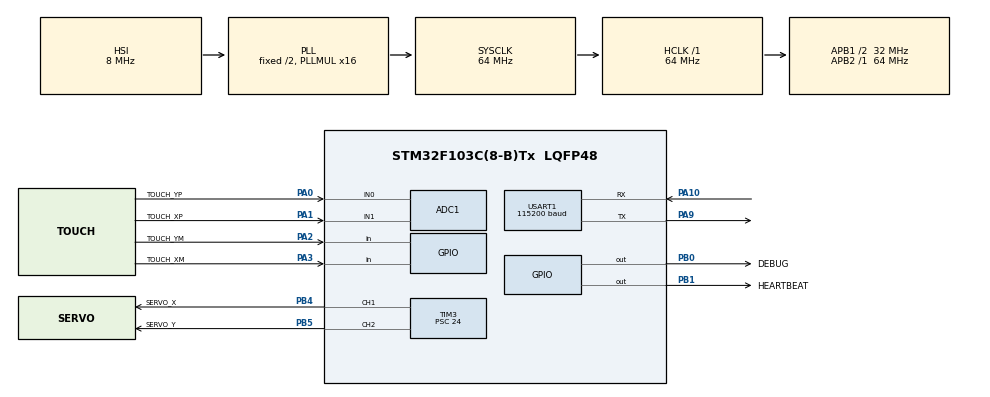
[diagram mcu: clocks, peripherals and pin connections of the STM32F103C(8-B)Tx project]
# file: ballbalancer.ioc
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ADC1.Channel-10\#ChannelRegularConversion=ADC_CHANNEL_0
ADC1.ContinuousConvMode=ENABLE
ADC1.EnableRegularConversion=ENABLE
ADC1.InjNumberOfConversion=0
ADC1.NbrOfConversionFlag=1
ADC1.Rank-10\#ChannelRegularConversion=1
ADC1.SamplingTime-10\#ChannelRegularConversion=ADC_SAMPLETIME_1CYCLE_5
ADC1.master=1
Dma.Request0=USART1_TX
Dma.Request1=USART1_RX
Dma.USART1_RX.1.Direction=DMA_PERIPH_TO_MEMORY
Dma.USART1_RX.1.Instance=DMA1_Channel5
Dma.USART1_RX.1.MemDataAlignment=DMA_MDATAALIGN_BYTE
Dma.USART1_RX.1.MemInc=DMA_MINC_ENABLE
Dma.USART1_RX.1.Mode=DMA_CIRCULAR
Dma.USART1_RX.1.PeriphDataAlignment=DMA_PDATAALIGN_BYTE
Dma.USART1_RX.1.PeriphInc=DMA_PINC_DISABLE
Dma.USART1_RX.1.Priority=DMA_PRIORITY_LOW
Dma.USART1_TX.0.Direction=DMA_MEMORY_TO_PERIPH
Dma.USART1_TX.0.Instance=DMA1_Channel4
Dma.USART1_TX.0.MemDataAlignment=DMA_MDATAALIGN_BYTE
Dma.USART1_TX.0.MemInc=DMA_MINC_ENABLE
Dma.USART1_TX.0.Mode=DMA_NORMAL
Dma.USART1_TX.0.PeriphDataAlignment=DMA_PDATAALIGN_BYTE
Dma.USART1_TX.0.PeriphInc=DMA_PINC_DISABLE
Dma.USART1_TX.0.Priority=DMA_PRIORITY_LOW
FREERTOS.INCLUDE_vTaskDelayUntil=1
FREERTOS.Tasks01=control,3,512,controlTask,As weak,NULL,Dynamic,NULL,NULL
FREERTOS.configTOTAL_HEAP_SIZE=10000
Mcu.Family=STM32F1
Mcu.Name=STM32F103C(8-B)Tx
Mcu.Package=LQFP48
NVIC.DMA1_Channel4_IRQn=true\:5\:0\:false\:false\:true\:true\:false
NVIC.DMA1_Channel5_IRQn=true\:5\:0\:false\:false\:true\:true\:false
NVIC.PriorityGroup=NVIC_PRIORITYGROUP_4
NVIC.TIM3_IRQn=true\:5\:0\:false\:false\:true\:true\:true
NVIC.USART1_IRQn=true\:5\:0\:false\:false\:true\:true\:true
PA0-WKUP.GPIO_Label=TOUCH_YP
PA0-WKUP.Signal=ADCx_IN0
PA1.GPIO_Label=TOUCH_XP
PA1.Signal=ADCx_IN1
PA10.Mode=Asynchronous
PA10.Signal=USART1_RX
PA13.Mode=Serial_Wire
PA13.Signal=SYS_JTMS-SWDIO
PA14.Mode=Serial_Wire
PA14.Signal=SYS_JTCK-SWCLK
PA2.GPIO_Label=TOUCH_YM
PA2.Signal=GPIO_Input
PA3.GPIO_Label=TOUCH_XM
PA3.Signal=GPIO_Input
PA9.Mode=Asynchronous
PA9.Signal=USART1_TX
PB0.GPIO_Label=DEBUG
PB0.Signal=GPIO_Output
PB1.GPIO_Label=HEARTBEAT
PB1.Signal=GPIO_Output
PB4.GPIO_Label=SERVO_X
PB4.Signal=S_TIM3_CH1
PB5.GPIO_Label=SERVO_Y
PB5.Signal=S_TIM3_CH2
ProjectManager.HeapSize=0x200
ProjectManager.StackSize=0x400
ProjectManager.TargetToolchain=SW4STM32
RCC.ADCPresc=RCC_ADCPCLK2_DIV6
RCC.AHBFreq_Value=64000000
RCC.APB1CLKDivider=RCC_HCLK_DIV2
RCC.APB1Freq_Value=32000000
RCC.APB1TimFreq_Value=64000000
RCC.APB2Freq_Value=64000000
RCC.APB2TimFreq_Value=64000000
RCC.HCLKFreq_Value=64000000
RCC.PLLMUL=RCC_PLL_MUL16
RCC.SYSCLKFreq_VALUE=64000000
RCC.SYSCLKSource=RCC_SYSCLKSOURCE_PLLCLK
RCC.USBFreq_Value=64000000
SH.ADCx_IN0.0=ADC1_IN0,IN0
SH.ADCx_IN1.0=ADC1_IN1,IN1
SH.S_TIM3_CH1.0=TIM3_CH1,PWM Generation1 CH1
SH.S_TIM3_CH2.0=TIM3_CH2,PWM Generation2 CH2
TIM3.AutoReloadPreload=TIM_AUTORELOAD_PRELOAD_ENABLE
TIM3.Channel-PWM\ Generation1\ CH1=TIM_CHANNEL_1
TIM3.Channel-PWM\ Generation2\ CH2=TIM_CHANNEL_2
TIM3.Period=0xc800
TIM3.Prescaler=24
USART1.BaudRate=115200
USART1.VirtualMode=VM_ASYNC
VP_FREERTOS_VS_ENABLE.Mode=Enabled
board=ballbalancer

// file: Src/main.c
/**
  ******************************************************************************
  * @file           : main.c
  * @brief          : Main program body
  ******************************************************************************
  * This notice applies to any and all portions of this file
  * that are not between comment pairs USER CODE BEGIN and
  * USER CODE END. Other portions of this file, whether
  * inserted by the user or by software development tools
  * are owned by their respective copyright owners.
  *
  * Copyright (c) 2019 STMicroelectronics International N.V.
  * All rights reserved.
  *
  * Redistribution and use in source and binary forms, with or without
  * modification, are permitted, provided that the following conditions are met:
  *
  * 1. Redistribution of source code must retain the above copyright notice,
  *    this list of conditions and the following disclaimer.
  * 2. Redistributions in binary form must reproduce the above copyright notice,
  *    this list of conditions and the following disclaimer in the documentation
  *    and/or other materials provided with the distribution.
  * 3. Neither the name of STMicroelectronics nor the names of other
  *    contributors to this software may be used to endorse or promote products
  *    derived from this software without specific written permission.
  * 4. This software, including modifications and/or derivative works of this
  *    software, must execute solely and exclusively on microcontroller or
  *    microprocessor devices manufactured by or for STMicroelectronics.
  * 5. Redistribution and use of this software other than as permitted under
  *    this license is void and will automatically terminate your rights under
  *    this license.
  *
  * THIS SOFTWARE IS PROVIDED BY STMICROELECTRONICS AND CONTRIBUTORS "AS IS"
  * AND ANY EXPRESS, IMPLIED OR STATUTORY WARRANTIES, INCLUDING, BUT NOT
  * LIMITED TO, THE IMPLIED WARRANTIES OF MERCHANTABILITY, FITNESS FOR A
  * PARTICULAR PURPOSE AND NON-INFRINGEMENT OF THIRD PARTY INTELLECTUAL PROPERTY
  * RIGHTS ARE DISCLAIMED TO THE FULLEST EXTENT PERMITTED BY LAW. IN NO EVENT
  * SHALL STMICROELECTRONICS OR CONTRIBUTORS BE LIABLE FOR ANY DIRECT, INDIRECT,
  * INCIDENTAL, SPECIAL, EXEMPLARY, OR CONSEQUENTIAL DAMAGES (INCLUDING, BUT NOT
  * LIMITED TO, PROCUREMENT OF SUBSTITUTE GOODS OR SERVICES; LOSS OF USE, DATA,
  * OR PROFITS; OR BUSINESS INTERRUPTION) HOWEVER CAUSED AND ON ANY THEORY OF
  * LIABILITY, WHETHER IN CONTRACT, STRICT LIABILITY, OR TORT (INCLUDING
  * NEGLIGENCE OR OTHERWISE) ARISING IN ANY WAY OUT OF THE USE OF THIS SOFTWARE,
  * EVEN IF ADVISED OF THE POSSIBILITY OF SUCH DAMAGE.
  *
  ******************************************************************************
  */
#include "main.h"
#include "stm32f1xx_hal.h"
#include "cmsis_os.h"
#include "adc.h"
#include "dma.h"
#include "tim.h"
#include "usart.h"
#include "gpio.h"

/* USER CODE BEGIN PV */
/* Private variables ---------------------------------------------------------*/

/* USER CODE END PV */

void SystemClock_Config(void);
void MX_FREERTOS_Init(void);

/* USER CODE BEGIN PFP */
/* Private function prototypes -----------------------------------------------*/

/* USER CODE END PFP */

int main(void)
{

  /* MCU Configuration----------------------------------------------------------*/

  /* Reset of all peripherals, Initializes the Flash interface and the Systick. */
  HAL_Init();

  /* Configure the system clock */
  SystemClock_Config();

  /* Initialize all configured peripherals */
  MX_GPIO_Init();
  MX_DMA_Init();
  MX_USART1_UART_Init();
  MX_ADC1_Init();
  MX_TIM3_Init();

  /* Call init function for freertos objects (in freertos.c) */
  MX_FREERTOS_Init();

  /* Start scheduler */
  osKernelStart();

  /* We should never get here as control is now taken by the scheduler */

  /* Infinite loop */
  while (1)
  {

  }

}

void SystemClock_Config(void)
{

  RCC_OscInitTypeDef RCC_OscInitStruct;
  RCC_ClkInitTypeDef RCC_ClkInitStruct;
  RCC_PeriphCLKInitTypeDef PeriphClkInit;

    /**Initializes the CPU, AHB and APB busses clocks
    */
  RCC_OscInitStruct.OscillatorType = RCC_OSCILLATORTYPE_HSI;
  RCC_OscInitStruct.HSIState = RCC_HSI_ON;
  RCC_OscInitStruct.HSICalibrationValue = 16;
  RCC_OscInitStruct.PLL.PLLState = RCC_PLL_ON;
  RCC_OscInitStruct.PLL.PLLSource = RCC_PLLSOURCE_HSI_DIV2;
  RCC_OscInitStruct.PLL.PLLMUL = RCC_PLL_MUL16;
  if (HAL_RCC_OscConfig(&RCC_OscInitStruct) != HAL_OK)
  {
    _Error_Handler(__FILE__, __LINE__);
  }

    /**Initializes the CPU, AHB and APB busses clocks
    */
  RCC_ClkInitStruct.ClockType = RCC_CLOCKTYPE_HCLK|RCC_CLOCKTYPE_SYSCLK
                              |RCC_CLOCKTYPE_PCLK1|RCC_CLOCKTYPE_PCLK2;
  RCC_ClkInitStruct.SYSCLKSource = RCC_SYSCLKSOURCE_PLLCLK;
  RCC_ClkInitStruct.AHBCLKDivider = RCC_SYSCLK_DIV1;
  RCC_ClkInitStruct.APB1CLKDivider = RCC_HCLK_DIV2;
  RCC_ClkInitStruct.APB2CLKDivider = RCC_HCLK_DIV1;

  if (HAL_RCC_ClockConfig(&RCC_ClkInitStruct, FLASH_LATENCY_2) != HAL_OK)
  {
    _Error_Handler(__FILE__, __LINE__);
  }

  PeriphClkInit.PeriphClockSelection = RCC_PERIPHCLK_ADC;
  PeriphClkInit.AdcClockSelection = RCC_ADCPCLK2_DIV6;
  if (HAL_RCCEx_PeriphCLKConfig(&PeriphClkInit) != HAL_OK)
  {
    _Error_Handler(__FILE__, __LINE__);
  }

    /**Configure the Systick interrupt time
    */
  HAL_SYSTICK_Config(HAL_RCC_GetHCLKFreq()/1000);

    /**Configure the Systick
    */
  HAL_SYSTICK_CLKSourceConfig(SYSTICK_CLKSOURCE_HCLK);

  /* SysTick_IRQn interrupt configuration */
  HAL_NVIC_SetPriority(SysTick_IRQn, 15, 0);
}

void _Error_Handler(char *file, int line)
{
  /* USER CODE BEGIN Error_Handler_Debug */
  /* User can add his own implementation to report the HAL error return state */
  asm("bkpt #1");
  while(1)
  {
  }
  /* USER CODE END Error_Handler_Debug */
}

/************************ (C) COPYRIGHT STMicroelectronics *****END OF FILE****/

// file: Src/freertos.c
/**
  ******************************************************************************
  * File Name          : freertos.c
  * Description        : Code for freertos applications
  ******************************************************************************
  * This notice applies to any and all portions of this file
  * that are not between comment pairs USER CODE BEGIN and
  * USER CODE END. Other portions of this file, whether
  * inserted by the user or by software development tools
  * are owned by their respective copyright owners.
  *
  * Copyright (c) 2019 STMicroelectronics International N.V.
  * All rights reserved.
  *
  * Redistribution and use in source and binary forms, with or without
  * modification, are permitted, provided that the following conditions are met:
  *
  * 1. Redistribution of source code must retain the above copyright notice,
  *    this list of conditions and the following disclaimer.
  * 2. Redistributions in binary form must reproduce the above copyright notice,
  *    this list of conditions and the following disclaimer in the documentation
  *    and/or other materials provided with the distribution.
  * 3. Neither the name of STMicroelectronics nor the names of other
  *    contributors to this software may be used to endorse or promote products
  *    derived from this software without specific written permission.
  * 4. This software, including modifications and/or derivative works of this
  *    software, must execute solely and exclusively on microcontroller or
  *    microprocessor devices manufactured by or for STMicroelectronics.
  * 5. Redistribution and use of this software other than as permitted under
  *    this license is void and will automatically terminate your rights under
  *    this license.
  *
  * THIS SOFTWARE IS PROVIDED BY STMICROELECTRONICS AND CONTRIBUTORS "AS IS"
  * AND ANY EXPRESS, IMPLIED OR STATUTORY WARRANTIES, INCLUDING, BUT NOT
  * LIMITED TO, THE IMPLIED WARRANTIES OF MERCHANTABILITY, FITNESS FOR A
  * PARTICULAR PURPOSE AND NON-INFRINGEMENT OF THIRD PARTY INTELLECTUAL PROPERTY
  * RIGHTS ARE DISCLAIMED TO THE FULLEST EXTENT PERMITTED BY LAW. IN NO EVENT
  * SHALL STMICROELECTRONICS OR CONTRIBUTORS BE LIABLE FOR ANY DIRECT, INDIRECT,
  * INCIDENTAL, SPECIAL, EXEMPLARY, OR CONSEQUENTIAL DAMAGES (INCLUDING, BUT NOT
  * LIMITED TO, PROCUREMENT OF SUBSTITUTE GOODS OR SERVICES; LOSS OF USE, DATA,
  * OR PROFITS; OR BUSINESS INTERRUPTION) HOWEVER CAUSED AND ON ANY THEORY OF
  * LIABILITY, WHETHER IN CONTRACT, STRICT LIABILITY, OR TORT (INCLUDING
  * NEGLIGENCE OR OTHERWISE) ARISING IN ANY WAY OUT OF THE USE OF THIS SOFTWARE,
  * EVEN IF ADVISED OF THE POSSIBILITY OF SUCH DAMAGE.
  *
  ******************************************************************************
  */

#include "FreeRTOS.h"
#include "task.h"
#include "cmsis_os.h"

/* USER CODE BEGIN Includes */
#include "stm32f1xx.h"
/* USER CODE END Includes */

osThreadId controlHandle;

void controlTask(void const * argument);

void MX_FREERTOS_Init(void); /* (MISRA C 2004 rule 8.1) */

/* Hook prototypes */

/* Init FreeRTOS */

void MX_FREERTOS_Init(void) {

  /* Create the thread(s) */
  /* definition and creation of control */
  osThreadDef(control, controlTask, osPriorityRealtime, 0, 512);
  controlHandle = osThreadCreate(osThread(control), NULL);

}

/* controlTask function */
__weak void controlTask(void const * argument)
{

  for(;;)
  {
    osDelay(1);
  }
}

/************************ (C) COPYRIGHT STMicroelectronics *****END OF FILE****/
